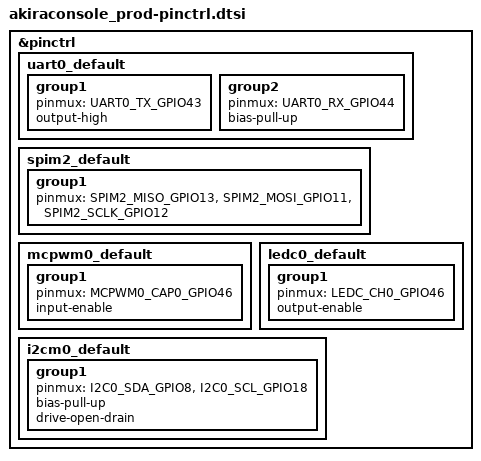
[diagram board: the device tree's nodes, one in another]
// SPDX-License-Identifier: Apache-2.0
// AkiraConsole Production — pin-control definitions
// All assignments derived from HWAkiraConsole schematic Rev A.2 (2026-03-10).

#include <zephyr/dt-bindings/pinctrl/esp-pinctrl-common.h>
#include <dt-bindings/pinctrl/esp32s3-pinctrl.h>
#include <zephyr/dt-bindings/pinctrl/esp32s3-gpio-sigmap.h>

&pinctrl {

	// -------------------------------------------------------------------------
	// UART0 — debug serial / shell
	// TX = GPIO43 (U0TXD), RX = GPIO44 (U0RXD)
	// Also bridged to CP2102N (U15) on J3 USB-UART connector.
	// -------------------------------------------------------------------------
	uart0_default: uart0_default {
		group1 {
			pinmux = <UART0_TX_GPIO43>;
			output-high;
		};
		group2 {
			pinmux = <UART0_RX_GPIO44>;
			bias-pull-up;
		};
	};

	// -------------------------------------------------------------------------
	// SPI2 — shared peripheral bus
	// MOSI = GPIO11 (SPI2.MOSI)
	// CLK  = GPIO12 (SPI2.CLK, via R93 0R — default populated)
	// MISO = GPIO13 (SPI2.MISO)
	//
	// CS lines are NOT listed here; they are controlled via cs-gpios in &spi2:
	//   CS0 (LR_CS)  — TCA6408 P6 (I2C GPIO expander)
	//   CS1 (TFT_CS) — GPIO10 (direct)
	//   CS2 (SD_CS)  — GPIO14 (direct)
	//   CS3 (CC_CS)  — TCA6408 P3 (I2C GPIO expander)
	// -------------------------------------------------------------------------
	spim2_default: spim2_default {
		group1 {
			pinmux = <SPIM2_MISO_GPIO13>,
			         <SPIM2_MOSI_GPIO11>,
			         <SPIM2_SCLK_GPIO12>;
		};
	};

	// -------------------------------------------------------------------------
	// GPIO46 — brightness wheel (RV1, RK10J12R0A0B) + AP2502 backlight EN
	//
	// RC relaxation oscillator: D2/D3 (BAT54J) + RV1 + C67 (10 nF) →
	// U5B → U5A (74LVC2G14 Schmitt trigger chain) → R63 → GPIO46.
	// Same net also drives AP2502 (U22) EN directly (disp backlight).
	// Oscillates at f = 1/(R×C) ≈ 9 kHz; duty cycle encodes pot position.
	// Range: 9 % (wheel full CW, max resistance) to 91 % (full CCW).
	//
	// DEFAULT mode: MCPWM0 capture — read duty cycle = read wheel position.
	// OVERRIDE mode: LEDC CH0 output — MCU drives brightness in software.
	// (Switch by re-routing GPIO46 pinmux; cannot do both simultaneously.)
	// -------------------------------------------------------------------------

	// Default: MCPWM0 capture input — pot reading
	mcpwm0_default: mcpwm0_default {
		group1 {
			pinmux = <MCPWM0_CAP0_GPIO46>;
			input-enable;
		};
	};

	// Override: LEDC CH0 output — software brightness control
	ledc0_default: ledc0_default {
		group1 {
			pinmux = <LEDC_CH0_GPIO46>;
			output-enable;
		};
	};

	// -------------------------------------------------------------------------
	// I2C0 — all internal I2C peripherals
	// SDA = GPIO8  (I2C.SDA)
	// SCL = GPIO18 (I2C.SCL)
	//
	// Devices on bus (7-bit addresses):
	//   0x21  TCA6408ARSV — GPIO expander (WRITE=0x42, READ=0x43)
	//   0x22  FUSB302BMPX — USB-C PD controller
	//   0x6A  LSM6DS3     — 6-axis IMU (SDO/SA0 → GND)
	//   0x6B  BQ25601RTW  — Li-Ion charger
	//   0x2D  LP5817      — backlight LED driver (0x34 = broadcast addr)
	//   0x48  SE050       — secure element 
	//   0x70  STC3115     — fuel gauge
	//   0x77  BME280      — env sensor (CSB → HIGH)
	// Pull-up resistors R26 (4.7k) and R27 (4.7k) on PCB.
	// -------------------------------------------------------------------------
	i2cm0_default: i2cm0_default {
		group1 {
			pinmux = <I2C0_SDA_GPIO8>,
			         <I2C0_SCL_GPIO18>;
			bias-pull-up;
			drive-open-drain;
		};
	};
};
